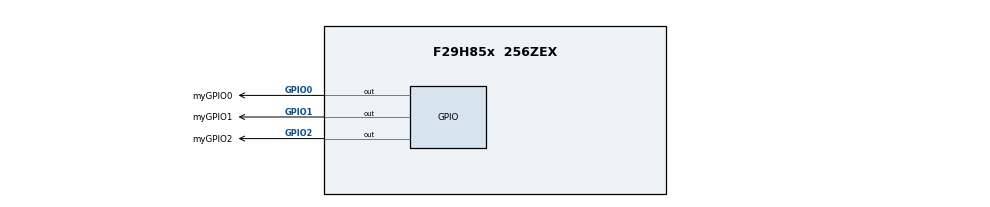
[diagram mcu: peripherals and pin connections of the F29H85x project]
/**
 * @cliArgs --device "F29H85x" --package "256ZEX" --part "F29H85x_256ZEX" --context "CPU1" --product "MCU_SDK_F29H85x@1.00.00.00"
 * @versions {"tool":"1.22.0+3877"}
 */

const divider15       = system.clockTree["PLL_REFDIV"];
divider15.divideValue = 1;

const multiplier1         = system.clockTree["PLL_IMULT"];
multiplier1.multiplyValue = 40;

const mux7       = system.clockTree["OSCCLKSRCSEL"];
mux7.inputSelect = "INTOSC2";

/**
 * Import the modules used in this configuration.
 */

const gpio             = scripting.addModule("/driverlib/gpio.js", {}, false);
const gpio1            = gpio.addInstance();
const gpio2            = gpio.addInstance();
const gpio3            = gpio.addInstance();
const jtag             = scripting.addModule("/driverlib/jtag.js");
const sysctl           = scripting.addModule("/driverlib/sysctl.js");

/**
 * Write custom configuration values to the imported modules.
 */
gpio1.$name           = "myGPIO0";
gpio1.gpioPin.$assign = "GPIO0";

gpio2.$name           = "myGPIO1";
gpio2.direction       = "GPIO_DIR_MODE_OUT";
gpio2.gpioPin.$assign = "GPIO1";

gpio3.$name           = "myGPIO2";
gpio3.direction       = "GPIO_DIR_MODE_OUT";
gpio3.gpioPin.$assign = "GPIO2";

sysctl.lpmWakeUpPin               = ["SYSCTL_LPMSEL_GPIO0"];
sysctl.registerWakeupInterrupt    = true;
sysctl.wakeupInt.interruptHandler = "wakeupISR";
